AUTOSAR XML (schema 4-2-2)
package /EB/SoftwareComponents
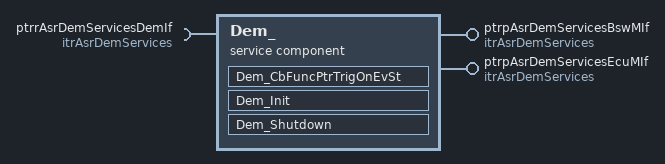
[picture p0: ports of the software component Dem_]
  service sw component type Dem_: category=ASR_Interfaces
    provide port ptrpAsrDemServicesBswMIf: provided-interface=itrAsrDemServices
    provide port ptrpAsrDemServicesEcuMIf: provided-interface=itrAsrDemServices
    require port ptrrAsrDemServicesDemIf: required-interface=itrAsrDemServices
    behavior Dem_IB: handle-termination-and-restart=NO-SUPPORT
      external trigger occurred event trDem_Callback_EventStatusChanged: start-on-event=Dem_CbFuncPtrTrigOnEvSt, trigger=ptrrAsrDemServicesDemIf.Dem_Callback_EventStatusChanged
      external trigger occurred event trModule_DemTriggerOnEventStatus: start-on-event=Dem_CbFuncPtrTrigOnEvSt, trigger=ptrrAsrDemServicesDemIf
      runnable Dem_CbFuncPtrTrigOnEvSt: symbol=Dem_CbFuncPtrTrigOnEvSt_OsApplication_0
      runnable Dem_Init
      runnable Dem_Shutdown
package /EB/TriggerInterfaces
  trigger interface itrAsrDemServices
    4 x trigger, all with trigger-period={cse-code=1000, cse-code-factor=0}:
      Dem_Callback_EventStatusChanged
      Dem_Init
      Dem_PreInit
      Dem_Shutdown
